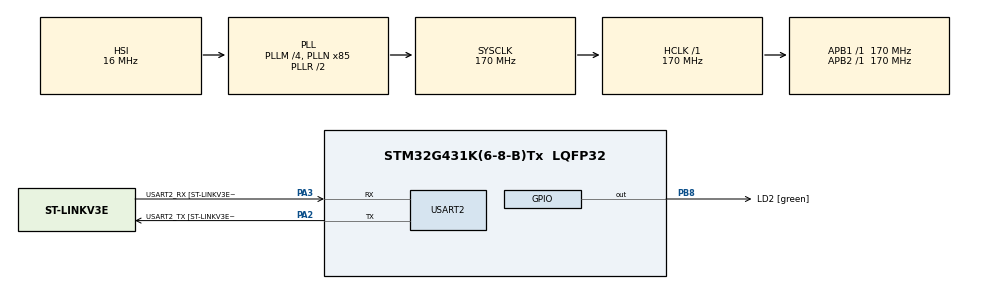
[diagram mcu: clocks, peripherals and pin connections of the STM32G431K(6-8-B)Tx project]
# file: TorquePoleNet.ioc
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Mcu.Family=STM32G4
Mcu.Name=STM32G431K(6-8-B)Tx
Mcu.Package=LQFP32
NVIC.PriorityGroup=NVIC_PRIORITYGROUP_4
NVIC.USART2_IRQn=true\:0\:0\:false\:false\:true\:true\:true\:true
PA13.GPIO_Label=T_SWDIO
PA13.Mode=Serial_Wire
PA13.Signal=SYS_JTMS-SWDIO
PA14.GPIO_Label=T_SWCLK
PA14.Mode=Serial_Wire
PA14.Signal=SYS_JTCK-SWCLK
PA2.GPIO_Label=USART2_TX [ST-LINKV3E_VCP_RX]
PA2.Mode=Asynchronous
PA2.Signal=USART2_TX
PA3.GPIO_Label=USART2_RX [ST-LINKV3E_VCP_TX]
PA3.Mode=Asynchronous
PA3.Signal=USART2_RX
PB3.GPIO_Label=T_SWO
PB3.Signal=SYS_JTDO-SWO
PB8-BOOT0.GPIO_Label=LD2 [green]
PB8-BOOT0.Signal=GPIO_Output
ProjectManager.HeapSize=0x800
ProjectManager.StackSize=0x800
ProjectManager.TargetToolchain=STM32CubeIDE
RCC.ADC12Freq_Value=170000000
RCC.AHBFreq_Value=170000000
RCC.APB1Freq_Value=170000000
RCC.APB1TimFreq_Value=170000000
RCC.APB2Freq_Value=170000000
RCC.APB2TimFreq_Value=170000000
RCC.CortexFreq_Value=170000000
RCC.EXTERNAL_CLOCK_VALUE=12288000
RCC.HCLKFreq_Value=170000000
RCC.HSE_VALUE=8000000
RCC.HSI48_VALUE=48000000
RCC.HSI_VALUE=16000000
RCC.LSE_VALUE=32768
RCC.PLLM=RCC_PLLM_DIV4
RCC.PLLN=85
RCC.SYSCLKFreq_VALUE=170000000
RCC.SYSCLKSource=RCC_SYSCLKSOURCE_PLLCLK
RCC.USBFreq_Value=170000000
RCC.VCOOutputFreq_Value=340000000
STMicroelectronics.X-CUBE-AI.8.1.0.ActivationBufferSizeList=1048
STMicroelectronics.X-CUBE-AI.8.1.0.ActivationBuffers=pool0
STMicroelectronics.X-CUBE-AI.8.1.0.ActivationNames=pool0
STMicroelectronics.X-CUBE-AI.8.1.0.ActivationSizes=AI_NETWORK_DATA_ACTIVATION_1_SIZE
STMicroelectronics.X-CUBE-AI.8.1.0.ApplicationCcDeviceJjApplication=ApplicationTemplate
STMicroelectronics.X-CUBE-AI.8.1.0.HeapSize=0x800
STMicroelectronics.X-CUBE-AI.8.1.0.InternalRamActivationBufferMaxSize=AI_NETWORK_DATA_ACTIVATIONS_SIZE
STMicroelectronics.X-CUBE-AI.8.1.0.LatestDirectoryUsed-7263f9b080abaf113eb647d25a2b932f3afe2a457c5dc165852855579e794b48=/home/tyler/MachineLearning/git/GuardDog/stm32
STMicroelectronics.X-CUBE-AI.8.1.0.MaximumNumberOfInputLayer=1
STMicroelectronics.X-CUBE-AI.8.1.0.MaximumNumberOfOutputLayer=3
STMicroelectronics.X-CUBE-AI.8.1.0.MaximumSizeOfInputLayer=1
STMicroelectronics.X-CUBE-AI.8.1.0.MaximumSizeOfOutputLayer=1,1,1
STMicroelectronics.X-CUBE-AI.8.1.0.ModelActualCompression-7263f9b080abaf113eb647d25a2b932f3afe2a457c5dc165852855579e794b48=0.0
STMicroelectronics.X-CUBE-AI.8.1.0.ModelCompression-7263f9b080abaf113eb647d25a2b932f3afe2a457c5dc165852855579e794b48=Lossless
STMicroelectronics.X-CUBE-AI.8.1.0.ModelFlashOccupation-7263f9b080abaf113eb647d25a2b932f3afe2a457c5dc165852855579e794b48=75560
STMicroelectronics.X-CUBE-AI.8.1.0.ModelHashList=7263f9b080abaf113eb647d25a2b932f3afe2a457c5dc165852855579e794b48
STMicroelectronics.X-CUBE-AI.8.1.0.ModelKind-7263f9b080abaf113eb647d25a2b932f3afe2a457c5dc165852855579e794b48=ONNX
STMicroelectronics.X-CUBE-AI.8.1.0.ModelMacc-7263f9b080abaf113eb647d25a2b932f3afe2a457c5dc165852855579e794b48=13692
STMicroelectronics.X-CUBE-AI.8.1.0.ModelName-7263f9b080abaf113eb647d25a2b932f3afe2a457c5dc165852855579e794b48=network
STMicroelectronics.X-CUBE-AI.8.1.0.ModelNameList=network
STMicroelectronics.X-CUBE-AI.8.1.0.ModelRamOccupation-7263f9b080abaf113eb647d25a2b932f3afe2a457c5dc165852855579e794b48=1048
STMicroelectronics.X-CUBE-AI.8.1.0.ModelStructureFile-7263f9b080abaf113eb647d25a2b932f3afe2a457c5dc165852855579e794b48=/home/tyler/MachineLearning/git/GuardDog/stm32/pendulum.onnx
STMicroelectronics.X-CUBE-AI.8.1.0.ModelType-7263f9b080abaf113eb647d25a2b932f3afe2a457c5dc165852855579e794b48=Saved model
STMicroelectronics.X-CUBE-AI.8.1.0.ReadyForCodeGeneration=true
STMicroelectronics.X-CUBE-AI.8.1.0.StackSize=0x800
STMicroelectronics.X-CUBE-AI.8.1.0.WorkingBufferStartAddrList=0xFFFFFFFF
STMicroelectronics.X-CUBE-AI.8.1.0.XAaCUBEAaAICcArtificialOoIntelligenceJjCore=true
STMicroelectronics.X-CUBE-AI.8.1.0.copyWeightToRam=false
STMicroelectronics.X-CUBE-AI.8.1.0.copyWeightToRam-7263f9b080abaf113eb647d25a2b932f3afe2a457c5dc165852855579e794b48=false
STMicroelectronics.X-CUBE-AI.8.1.0.customLayerConfigEnabled=false
STMicroelectronics.X-CUBE-AI.8.1.0.customLayerConfigEnabled-7263f9b080abaf113eb647d25a2b932f3afe2a457c5dc165852855579e794b48=false
STMicroelectronics.X-CUBE-AI.8.1.0.noOnnxIoTranspose=false
STMicroelectronics.X-CUBE-AI.8.1.0.noOnnxIoTranspose-7263f9b080abaf113eb647d25a2b932f3afe2a457c5dc165852855579e794b48=false
STMicroelectronics.X-CUBE-AI.8.1.0.useInputAllocation=true
STMicroelectronics.X-CUBE-AI.8.1.0.useInputAllocation-7263f9b080abaf113eb647d25a2b932f3afe2a457c5dc165852855579e794b48=true
STMicroelectronics.X-CUBE-AI.8.1.0.useOutputAllocation=true
STMicroelectronics.X-CUBE-AI.8.1.0.useOutputAllocation-7263f9b080abaf113eb647d25a2b932f3afe2a457c5dc165852855579e794b48=true
TIM2.Prescaler=170
USART2.VirtualMode-Asynchronous=VM_ASYNC
USART2.WordLength=WORDLENGTH_8B
VP_CRC_VS_CRC.Mode=CRC_Activate
VP_STMicroelectronics.X-CUBE-AI_VS_ArtificialOoIntelligenceJjXAaCUBEAaAI_8.1.0.Mode=ArtificialOoIntelligenceJjXAaCUBEAaAI
VP_STMicroelectronics.X-CUBE-AI_VS_DeviceJjApplication_8.1.0.Mode=DeviceJjApplication
VP_SYS_VS_DBSignals.Mode=DisableDeadBatterySignals
VP_TIM2_VS_ClockSourceINT.Mode=Internal
board=NUCLEO-G431KB

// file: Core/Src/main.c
/* USER CODE BEGIN Header */
/**
  ******************************************************************************
  * @file           : main.c
  * @brief          : Main program body
  ******************************************************************************
  * @attention
  *
  * Copyright (c) 2024 STMicroelectronics.
  * All rights reserved.
  *
  * This software is licensed under terms that can be found in the LICENSE file
  * in the root directory of this software component.
  * If no LICENSE file comes with this software, it is provided AS-IS.
  *
  ******************************************************************************
  */
/* USER CODE END Header */
#include "main.h"
#include "crc.h"
#include "tim.h"
#include "usart.h"
#include "gpio.h"
#include "app_x-cube-ai.h"

/* USER CODE BEGIN Includes */
#include <stdint.h>
#include "network.h"
/* USER CODE END Includes */

/* USER CODE BEGIN PV */
union floatUnion {
    float floatValue[4];
    uint8_t bytes[4 * sizeof(float)];
};
union floatUnion data;

ai_float in_data1[AI_NETWORK_IN_1_SIZE];
ai_float out_data1[AI_NETWORK_OUT_1_SIZE];
ai_float out_data2[AI_NETWORK_OUT_2_SIZE];
ai_float out_data3[AI_NETWORK_OUT_3_SIZE];
uint8_t data_flag;
/* USER CODE END PV */

void SystemClock_Config(void);

int main(void)
{
  /* USER CODE BEGIN 1 */
  data_flag=0;
  /* USER CODE END 1 */

  /* MCU Configuration--------------------------------------------------------*/

  /* Reset of all peripherals, Initializes the Flash interface and the Systick. */
  HAL_Init();

  /* Configure the system clock */
  SystemClock_Config();

  /* Initialize all configured peripherals */
  MX_GPIO_Init();
  MX_USART2_UART_Init();
  MX_CRC_Init();
  MX_TIM2_Init();
  MX_X_CUBE_AI_Init();
  /* USER CODE BEGIN 2 */
  HAL_UART_Receive_IT(&huart2, data.bytes, sizeof(data.bytes));

  /* USER CODE END 2 */

  /* Infinite loop */
  /* USER CODE BEGIN WHILE */

  while (1)
  {
//    HAL_UART_Transmit(&huart2, data.bytes, sizeof(data.bytes), 100);

    // Read 16 bytes into data.bytes
//    HAL_UART_Receive(&huart2, data.bytes, sizeof(data.bytes), 1000);

    if(data_flag)
    {

      TIM2->CNT = 0;
      HAL_TIM_Base_Start(&htim2);
      in_data1[0] = data.floatValue[0]; // Sin Encoding
      in_data1[1] = data.floatValue[1]; // Cosine Encoding
      in_data1[2] = data.floatValue[2]; // Velocity
      MX_X_CUBE_AI_Process();
      HAL_TIM_Base_Stop(&htim2);
      data.floatValue[0] = out_data1[0]; // Value
      data.floatValue[1] = out_data2[0]; // Mu
      data.floatValue[2] = out_data3[0]; // STD
      data.floatValue[3] = (float)TIM2->CNT/(1000000); // Execution Time
      data_flag = 0;
      HAL_UART_Transmit(&huart2, data.bytes, sizeof(data.bytes), 100);
      HAL_UART_Receive_IT(&huart2, data.bytes, sizeof(data.bytes));
    }
    /* USER CODE END WHILE */

  }
}

void SystemClock_Config(void)
{
  RCC_OscInitTypeDef RCC_OscInitStruct = {0};
  RCC_ClkInitTypeDef RCC_ClkInitStruct = {0};

  /** Configure the main internal regulator output voltage
  */
  HAL_PWREx_ControlVoltageScaling(PWR_REGULATOR_VOLTAGE_SCALE1_BOOST);

  /** Initializes the RCC Oscillators according to the specified parameters
  * in the RCC_OscInitTypeDef structure.
  */
  RCC_OscInitStruct.OscillatorType = RCC_OSCILLATORTYPE_HSI;
  RCC_OscInitStruct.HSIState = RCC_HSI_ON;
  RCC_OscInitStruct.HSICalibrationValue = RCC_HSICALIBRATION_DEFAULT;
  RCC_OscInitStruct.PLL.PLLState = RCC_PLL_ON;
  RCC_OscInitStruct.PLL.PLLSource = RCC_PLLSOURCE_HSI;
  RCC_OscInitStruct.PLL.PLLM = RCC_PLLM_DIV4;
  RCC_OscInitStruct.PLL.PLLN = 85;
  RCC_OscInitStruct.PLL.PLLP = RCC_PLLP_DIV2;
  RCC_OscInitStruct.PLL.PLLQ = RCC_PLLQ_DIV2;
  RCC_OscInitStruct.PLL.PLLR = RCC_PLLR_DIV2;
  if (HAL_RCC_OscConfig(&RCC_OscInitStruct) != HAL_OK)
  {
    Error_Handler();
  }

  /** Initializes the CPU, AHB and APB buses clocks
  */
  RCC_ClkInitStruct.ClockType = RCC_CLOCKTYPE_HCLK|RCC_CLOCKTYPE_SYSCLK
                              |RCC_CLOCKTYPE_PCLK1|RCC_CLOCKTYPE_PCLK2;
  RCC_ClkInitStruct.SYSCLKSource = RCC_SYSCLKSOURCE_PLLCLK;
  RCC_ClkInitStruct.AHBCLKDivider = RCC_SYSCLK_DIV1;
  RCC_ClkInitStruct.APB1CLKDivider = RCC_HCLK_DIV1;
  RCC_ClkInitStruct.APB2CLKDivider = RCC_HCLK_DIV1;

  if (HAL_RCC_ClockConfig(&RCC_ClkInitStruct, FLASH_LATENCY_4) != HAL_OK)
  {
    Error_Handler();
  }
}

/* USER CODE BEGIN 4 */
void HAL_UART_RxCpltCallback(UART_HandleTypeDef *huart)
{
  // We will set a data flag here and execute in the main loop
  data_flag = 1;
}
void HAL_UART_TxCpltCallback(UART_HandleTypeDef *huart)
{

}

/* USER CODE END 4 */

void Error_Handler(void)
{
  __disable_irq();
  while (1)
  {
  }
}
